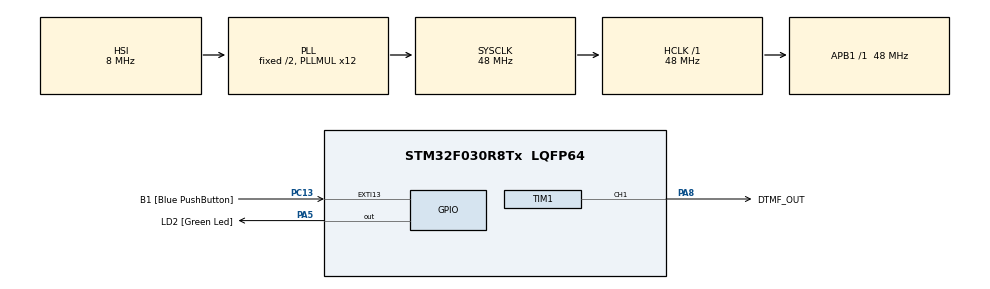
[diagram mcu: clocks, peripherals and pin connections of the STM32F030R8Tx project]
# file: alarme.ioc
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Mcu.Family=STM32F0
Mcu.Name=STM32F030R8Tx
Mcu.Package=LQFP64
Mcu.UserConstants=PWM_FREQ,0xff
NVIC.TIM1_BRK_UP_TRG_COM_IRQn=true\:0\:0\:false\:false\:true
NVIC.TIM6_IRQn=true\:0\:0\:false\:false\:true
PA13.GPIO_Label=TMS
PA13.Signal=SYS_SWDIO
PA14.GPIO_Label=TCK
PA14.Signal=SYS_SWCLK
PA2.GPIO_Label=USART_TX
PA2.GPIO_Mode=GPIO_MODE_AF_PP
PA2.GPIO_PuPd=GPIO_NOPULL
PA2.GPIO_Speed=GPIO_SPEED_FREQ_LOW
PA2.Signal=USART2_TX
PA3.GPIO_Label=USART_RX
PA3.GPIO_Mode=GPIO_MODE_AF_PP
PA3.GPIO_PuPd=GPIO_NOPULL
PA3.GPIO_Speed=GPIO_SPEED_FREQ_LOW
PA3.Signal=USART2_RX
PA5.GPIO_Label=LD2 [Green Led]
PA5.GPIO_Mode=GPIO_MODE_OUTPUT_PP
PA5.GPIO_PuPd=GPIO_NOPULL
PA5.GPIO_Speed=GPIO_SPEED_FREQ_LOW
PA5.Signal=GPIO_Output
PA8.GPIO_Label=DTMF_OUT
PA8.Signal=S_TIM1_CH1
PC13.GPIO_Label=B1 [Blue PushButton]
PC13.GPIO_ModeDefaultEXTI=GPIO_MODE_EVT_RISING
PC13.Signal=GPXTI13
PC14-OSC32_IN.Signal=RCC_OSC32_IN
PC15-OSC32_OUT.Signal=RCC_OSC32_OUT
PF0-OSC_IN.Signal=RCC_OSC_IN
PF1-OSC_OUT.Signal=RCC_OSC_OUT
ProjectManager.HeapSize=0x200
ProjectManager.StackSize=0x400
ProjectManager.TargetToolchain=MDK-ARM V5
RCC.AHBFreq_Value=48000000
RCC.APB1Freq_Value=48000000
RCC.APB1TimFreq_Value=48000000
RCC.HCLKFreq_Value=48000000
RCC.PLLMUL=RCC_PLL_MUL12
RCC.SYSCLKFreq_VALUE=48000000
RCC.SYSCLKSource=RCC_SYSCLKSOURCE_PLLCLK
SH.S_TIM1_CH1.0=TIM1_CH1,PWM Generation1 CH1
TIM1.AutomaticOutput=TIM_AUTOMATICOUTPUT_DISABLE
TIM1.CounterMode=TIM_COUNTERMODE_CENTERALIGNED1
TIM1.OCFastMode_PWM-PWM\ Generation1\ CH1=TIM_OCFAST_ENABLE
TIM1.Period=PWM_FREQ
TIM1.Prescaler=3
TIM1.Pulse-PWM\ Generation1\ CH1=PWM_FREQ/2
TIM6.Period=15999
TIM6.Prescaler=3
VP_TIM1_VS_ClockSourceINT.Mode=Internal
VP_TIM6_VS_ClockSourceINT.Mode=Enable_Timer
board=NUCLEO-F030R8

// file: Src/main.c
/**
  ******************************************************************************
  * File Name          : main.c
  * Description        : Main program body
  ******************************************************************************
  *
  * COPYRIGHT(c) 2016 STMicroelectronics
  *
  * Redistribution and use in source and binary forms, with or without modification,
  * are permitted provided that the following conditions are met:
  *   1. Redistributions of source code must retain the above copyright notice,
  *      this list of conditions and the following disclaimer.
  *   2. Redistributions in binary form must reproduce the above copyright notice,
  *      this list of conditions and the following disclaimer in the documentation
  *      and/or other materials provided with the distribution.
  *   3. Neither the name of STMicroelectronics nor the names of its contributors
  *      may be used to endorse or promote products derived from this software
  *      without specific prior written permission.
  *
  * THIS SOFTWARE IS PROVIDED BY THE COPYRIGHT HOLDERS AND CONTRIBUTORS "AS IS"
  * AND ANY EXPRESS OR IMPLIED WARRANTIES, INCLUDING, BUT NOT LIMITED TO, THE
  * IMPLIED WARRANTIES OF MERCHANTABILITY AND FITNESS FOR A PARTICULAR PURPOSE ARE
  * DISCLAIMED. IN NO EVENT SHALL THE COPYRIGHT HOLDER OR CONTRIBUTORS BE LIABLE
  * FOR ANY DIRECT, INDIRECT, INCIDENTAL, SPECIAL, EXEMPLARY, OR CONSEQUENTIAL
  * DAMAGES (INCLUDING, BUT NOT LIMITED TO, PROCUREMENT OF SUBSTITUTE GOODS OR
  * SERVICES; LOSS OF USE, DATA, OR PROFITS; OR BUSINESS INTERRUPTION) HOWEVER
  * CAUSED AND ON ANY THEORY OF LIABILITY, WHETHER IN CONTRACT, STRICT LIABILITY,
  * OR TORT (INCLUDING NEGLIGENCE OR OTHERWISE) ARISING IN ANY WAY OUT OF THE USE
  * OF THIS SOFTWARE, EVEN IF ADVISED OF THE POSSIBILITY OF SUCH DAMAGE.
  *
  ******************************************************************************
  */
#include "main.h"
#include "stm32f0xx_hal.h"
#include "tim.h"
#include "gpio.h"

/* USER CODE BEGIN Includes */
#include "dtmf.h"
/* USER CODE END Includes */

/* USER CODE BEGIN PV */
/* Private variables ---------------------------------------------------------*/
unsigned char send_tone,f_high=0,f_low=0;
unsigned int t_tone;
unsigned char num[16],pt=0;
uint8_t dial_flag=1;
/* USER CODE END PV */

void SystemClock_Config(void);
void Error_Handler(void);

/* USER CODE BEGIN PFP */
/* Private function prototypes -----------------------------------------------*/
void Demo_Init (void);
void Break_Tone (void);
void Dial_Number (uint8_t *pt);
/* USER CODE END PFP */

int main(void)
{

  /* MCU Configuration----------------------------------------------------------*/

  /* Reset of all peripherals, Initializes the Flash interface and the Systick. */
  HAL_Init();

  /* Configure the system clock */
  SystemClock_Config();

  /* Initialize all configured peripherals */
  MX_GPIO_Init();
  MX_TIM1_Init();
  MX_TIM6_Init();

  /* USER CODE BEGIN 2 */
  init_dtmf();
  Demo_Init();

  //Put the number to dial: in this demo, my cell 11 985650055
  num[0] =  9;
  num[1] =  8;
  num[2] =  5;
  num[3] =  6;
  num[4] =  5;
  num[5] =  0;
  num[6] =  0;
  num[7] =  5;
  num[8] =  5;
  num[9] =  0xFF;
//  num[10] = 0;
//  num[11] = 0;
//  num[12] = 5;
//  num[13] = 5;
//  num[14] = 0xFF;
  /* USER CODE END 2 */

  /* Infinite loop */
  /* USER CODE BEGIN WHILE */
  dial_flag =1;
  while (1)
  {
  /* USER CODE END WHILE */

  /* USER CODE BEGIN 3 */
    if (dial_flag)
    {
      Dial_Number(&num[0]);
      HAL_Delay(2000);
//      dial_flag =1;
    }
  }
  /* USER CODE END 3 */

}

/** System Clock Configuration
*/
void SystemClock_Config(void)
{

  RCC_OscInitTypeDef RCC_OscInitStruct;
  RCC_ClkInitTypeDef RCC_ClkInitStruct;

    /**Initializes the CPU, AHB and APB busses clocks
    */
  RCC_OscInitStruct.OscillatorType = RCC_OSCILLATORTYPE_HSI;
  RCC_OscInitStruct.HSIState = RCC_HSI_ON;
  RCC_OscInitStruct.HSICalibrationValue = 16;
  RCC_OscInitStruct.PLL.PLLState = RCC_PLL_ON;
  RCC_OscInitStruct.PLL.PLLSource = RCC_PLLSOURCE_HSI;
  RCC_OscInitStruct.PLL.PLLMUL = RCC_PLL_MUL12;
  RCC_OscInitStruct.PLL.PREDIV = RCC_PREDIV_DIV1;
  if (HAL_RCC_OscConfig(&RCC_OscInitStruct) != HAL_OK)
  {
    Error_Handler();
  }

    /**Initializes the CPU, AHB and APB busses clocks
    */
  RCC_ClkInitStruct.ClockType = RCC_CLOCKTYPE_HCLK|RCC_CLOCKTYPE_SYSCLK
                              |RCC_CLOCKTYPE_PCLK1;
  RCC_ClkInitStruct.SYSCLKSource = RCC_SYSCLKSOURCE_PLLCLK;
  RCC_ClkInitStruct.AHBCLKDivider = RCC_SYSCLK_DIV1;
  RCC_ClkInitStruct.APB1CLKDivider = RCC_HCLK_DIV1;

  if (HAL_RCC_ClockConfig(&RCC_ClkInitStruct, FLASH_LATENCY_1) != HAL_OK)
  {
    Error_Handler();
  }

    /**Configure the Systick interrupt time
    */
  HAL_SYSTICK_Config(HAL_RCC_GetHCLKFreq()/1000);

    /**Configure the Systick
    */
  HAL_SYSTICK_CLKSourceConfig(SYSTICK_CLKSOURCE_HCLK);

  /* SysTick_IRQn interrupt configuration */
  HAL_NVIC_SetPriority(SysTick_IRQn, 0, 0);
}

/* USER CODE BEGIN 4 */
void Demo_Init (void)
{
  HAL_GPIO_WritePin(DTMF_OUT_GPIO_Port, DTMF_OUT_Pin, GPIO_PIN_RESET);
//  HAL_TIM_Base_Start_IT(&htim6);
}

void Break_Tone (void)
{
  /* TIM1 Main Output Disable */
  while(HAL_TIM_PWM_GetState(&htim1) == HAL_TIM_STATE_BUSY);

  HAL_TIM_PWM_Stop(&htim1,TIM_CHANNEL_1);
  HAL_TIM_Base_Stop_IT(&htim1);
  HAL_GPIO_WritePin(DTMF_OUT_GPIO_Port, DTMF_OUT_Pin, GPIO_PIN_RESET);
  t_tone = 100;

  HAL_Delay(t_tone);
}

void Dial_Number (uint8_t *pt)
{
  while ((*pt) != 0xFF)
  {
    t_tone = 200;
    Send_Digit_Tone(*pt);
    HAL_Delay(t_tone);
    Break_Tone();
    pt++;
  }
  dial_flag =0;
}
/* USER CODE END 4 */

void Error_Handler(void)
{
  while(1)
  {
  }
}

/************************ (C) COPYRIGHT STMicroelectronics *****END OF FILE****/
